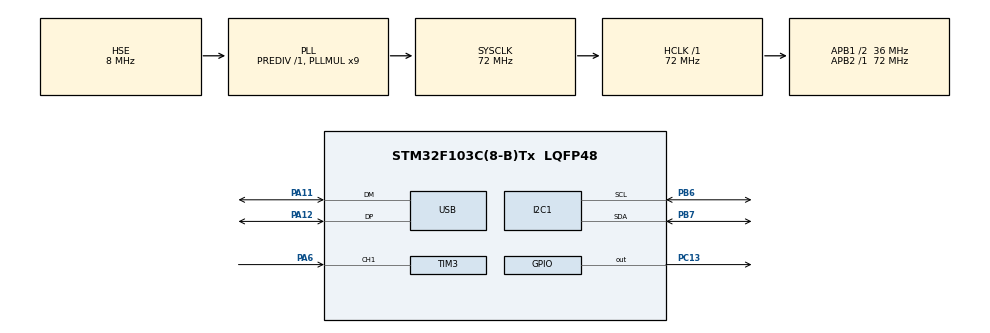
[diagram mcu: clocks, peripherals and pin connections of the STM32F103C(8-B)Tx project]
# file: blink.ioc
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Dma.I2C1_TX.0.Direction=DMA_MEMORY_TO_PERIPH
Dma.I2C1_TX.0.Instance=DMA1_Channel6
Dma.I2C1_TX.0.MemDataAlignment=DMA_MDATAALIGN_BYTE
Dma.I2C1_TX.0.MemInc=DMA_MINC_ENABLE
Dma.I2C1_TX.0.Mode=DMA_NORMAL
Dma.I2C1_TX.0.PeriphDataAlignment=DMA_PDATAALIGN_BYTE
Dma.I2C1_TX.0.PeriphInc=DMA_PINC_DISABLE
Dma.I2C1_TX.0.Priority=DMA_PRIORITY_LOW
Dma.Request0=I2C1_TX
FREERTOS.BinarySemaphores01=sendTelemetryToUsbSemaphore,Dynamic,NULL
FREERTOS.Tasks01=defaultTask,0,128,StartDefaultTask,Default,NULL
FREERTOS.configTOTAL_HEAP_SIZE=6144
FREERTOS.configUSE_COUNTING_SEMAPHORES=1
Mcu.Family=STM32F1
Mcu.Name=STM32F103C(8-B)Tx
Mcu.Package=LQFP48
NVIC.DMA1_Channel6_IRQn=true\:5\:0\:false\:false\:true\:true\:false
NVIC.I2C1_ER_IRQn=true\:5\:0\:false\:false\:true\:true\:true
NVIC.I2C1_EV_IRQn=true\:5\:0\:false\:false\:true\:true\:true
NVIC.PriorityGroup=NVIC_PRIORITYGROUP_4
NVIC.TIM3_IRQn=true\:5\:0\:false\:false\:true\:true\:true
NVIC.TIM4_IRQn=true\:0\:0\:false\:false\:true\:false\:false
NVIC.TimeBase=TIM4_IRQn
NVIC.TimeBaseIP=TIM4
NVIC.USB_LP_CAN1_RX0_IRQn=true\:5\:0\:false\:false\:true\:true\:false
PA11.Mode=Device
PA11.Signal=USB_DM
PA12.Mode=Device
PA12.Signal=USB_DP
PA13.Mode=Serial_Wire
PA13.Signal=SYS_JTMS-SWDIO
PA14.Mode=Serial_Wire
PA14.Signal=SYS_JTCK-SWCLK
PA6.Signal=S_TIM3_CH1
PB6.Mode=I2C
PB6.Signal=I2C1_SCL
PB7.Mode=I2C
PB7.Signal=I2C1_SDA
PC13-TAMPER-RTC.Signal=GPIO_Output
PD0-OSC_IN.Mode=HSE-External-Oscillator
PD0-OSC_IN.Signal=RCC_OSC_IN
PD1-OSC_OUT.Mode=HSE-External-Oscillator
PD1-OSC_OUT.Signal=RCC_OSC_OUT
ProjectManager.HeapSize=0x200
ProjectManager.StackSize=0x400
ProjectManager.TargetToolchain=SW4STM32
RCC.AHBFreq_Value=72000000
RCC.APB1CLKDivider=RCC_HCLK_DIV2
RCC.APB1Freq_Value=36000000
RCC.APB1TimFreq_Value=72000000
RCC.APB2Freq_Value=72000000
RCC.APB2TimFreq_Value=72000000
RCC.HCLKFreq_Value=72000000
RCC.PLLMUL=RCC_PLL_MUL9
RCC.PLLSourceVirtual=RCC_PLLSOURCE_HSE
RCC.SYSCLKFreq_VALUE=72000000
RCC.SYSCLKSource=RCC_SYSCLKSOURCE_PLLCLK
RCC.USBFreq_Value=48000000
RCC.USBPrescaler=RCC_USBCLKSOURCE_PLL_DIV1_5
SH.S_TIM3_CH1.0=TIM3_CH1,Input_Capture1_from_TI1
TIM3.Channel-Input_Capture1_from_TI1=TIM_CHANNEL_1
TIM3.ICPolarity_CH1=TIM_INPUTCHANNELPOLARITY_FALLING
TIM3.Period=65534
TIM3.Prescaler=71
USB_DEVICE.CLASS_NAME_FS=CDC
USB_DEVICE.VirtualMode=Cdc
USB_DEVICE.VirtualModeFS=Cdc_FS
VP_FREERTOS_VS_ENABLE.Mode=Enabled
VP_SYS_VS_tim4.Mode=TIM4
VP_USB_DEVICE_VS_USB_DEVICE_CDC_FS.Mode=CDC_FS
board=blink

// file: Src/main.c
/**
  ******************************************************************************
  * File Name          : main.c
  * Description        : Main program body
  ******************************************************************************
  * This notice applies to any and all portions of this file
  * that are not between comment pairs USER CODE BEGIN and
  * USER CODE END. Other portions of this file, whether
  * inserted by the user or by software development tools
  * are owned by their respective copyright owners.
  *
  * Copyright (c) 2018 STMicroelectronics International N.V.
  * All rights reserved.
  *
  * Redistribution and use in source and binary forms, with or without
  * modification, are permitted, provided that the following conditions are met:
  *
  * 1. Redistribution of source code must retain the above copyright notice,
  *    this list of conditions and the following disclaimer.
  * 2. Redistributions in binary form must reproduce the above copyright notice,
  *    this list of conditions and the following disclaimer in the documentation
  *    and/or other materials provided with the distribution.
  * 3. Neither the name of STMicroelectronics nor the names of other
  *    contributors to this software may be used to endorse or promote products
  *    derived from this software without specific written permission.
  * 4. This software, including modifications and/or derivative works of this
  *    software, must execute solely and exclusively on microcontroller or
  *    microprocessor devices manufactured by or for STMicroelectronics.
  * 5. Redistribution and use of this software other than as permitted under
  *    this license is void and will automatically terminate your rights under
  *    this license.
  *
  * THIS SOFTWARE IS PROVIDED BY STMICROELECTRONICS AND CONTRIBUTORS "AS IS"
  * AND ANY EXPRESS, IMPLIED OR STATUTORY WARRANTIES, INCLUDING, BUT NOT
  * LIMITED TO, THE IMPLIED WARRANTIES OF MERCHANTABILITY, FITNESS FOR A
  * PARTICULAR PURPOSE AND NON-INFRINGEMENT OF THIRD PARTY INTELLECTUAL PROPERTY
  * RIGHTS ARE DISCLAIMED TO THE FULLEST EXTENT PERMITTED BY LAW. IN NO EVENT
  * SHALL STMICROELECTRONICS OR CONTRIBUTORS BE LIABLE FOR ANY DIRECT, INDIRECT,
  * INCIDENTAL, SPECIAL, EXEMPLARY, OR CONSEQUENTIAL DAMAGES (INCLUDING, BUT NOT
  * LIMITED TO, PROCUREMENT OF SUBSTITUTE GOODS OR SERVICES; LOSS OF USE, DATA,
  * OR PROFITS; OR BUSINESS INTERRUPTION) HOWEVER CAUSED AND ON ANY THEORY OF
  * LIABILITY, WHETHER IN CONTRACT, STRICT LIABILITY, OR TORT (INCLUDING
  * NEGLIGENCE OR OTHERWISE) ARISING IN ANY WAY OUT OF THE USE OF THIS SOFTWARE,
  * EVEN IF ADVISED OF THE POSSIBILITY OF SUCH DAMAGE.
  *
  ******************************************************************************
  */

#include "main.h"
#include "stm32f1xx_hal.h"
#include "cmsis_os.h"
#include "usb_device.h"

/* USER CODE BEGIN Includes */
#include <lesson5.h>
/* USER CODE END Includes */

I2C_HandleTypeDef hi2c1;
DMA_HandleTypeDef hdma_i2c1_tx;

TIM_HandleTypeDef htim3;

//osThreadId defaultTaskHandle;
osSemaphoreId sendTelemetryToUsbSemaphoreHandle;

/* USER CODE BEGIN PV */
/* Private variables ---------------------------------------------------------*/
osThreadId displayOutputTask;
osThreadId tempratureTask;
osThreadId sendTelemetryToUsb;
/* USER CODE END PV */

void SystemClock_Config(void);
static void MX_GPIO_Init(void);
static void MX_DMA_Init(void);
static void MX_I2C1_Init(void);
static void MX_TIM3_Init(void);
//void StartDefaultTask(void const * argument);

/* USER CODE BEGIN PFP */

/* Private function prototypes -----------------------------------------------*/

/* USER CODE END PFP */

int main(void)
{

  /* MCU Configuration----------------------------------------------------------*/

  /* Reset of all peripherals, Initializes the Flash interface and the Systick. */
  HAL_Init();

  /* Configure the system clock */
  SystemClock_Config();

  /* Initialize all configured peripherals */
  MX_GPIO_Init();
  MX_DMA_Init();
  MX_I2C1_Init();
  MX_TIM3_Init();

  /* USER CODE BEGIN 2 */
  MX_USB_DEVICE_Init();
  /* USER CODE END 2 */

  /* Create the semaphores(s) */
  /* definition and creation of sendTelemetryToUsbSemaphore */
  osSemaphoreDef(sendTelemetryToUsbSemaphore);
  sendTelemetryToUsbSemaphoreHandle = osSemaphoreCreate(osSemaphore(sendTelemetryToUsbSemaphore), 1);

  /* Create the thread(s) */
  /* definition and creation of defaultTask */
//  osThreadDef(defaultTask, StartDefaultTask, osPriorityNormal, 0, 128);
//  defaultTaskHandle = osThreadCreate(osThread(defaultTask), NULL);

  /* USER CODE BEGIN RTOS_THREADS */
  osThreadDef(sendTelemetryToUsb, SendTelemetryToUsb, osPriorityRealtime, 1, 128);
  sendTelemetryToUsb = osThreadCreate(osThread(sendTelemetryToUsb), NULL);

  osThreadDef(tempratureTask, TemperatureTask, osPriorityAboveNormal, 1, 128);
  tempratureTask = osThreadCreate(osThread(tempratureTask), NULL);

  osThreadDef(displayOutputTask, DisplayOutputTask, osPriorityNormal, 1, 128);
  displayOutputTask = osThreadCreate(osThread(displayOutputTask), NULL);
  /* USER CODE END RTOS_THREADS */

  /* Start scheduler */
  osKernelStart();

  /* We should never get here as control is now taken by the scheduler */

  /* Infinite loop */
  while (1) {

  }

}

/** System Clock Configuration
*/
void SystemClock_Config(void)
{

  RCC_OscInitTypeDef RCC_OscInitStruct;
  RCC_ClkInitTypeDef RCC_ClkInitStruct;
  RCC_PeriphCLKInitTypeDef PeriphClkInit;

    /**Initializes the CPU, AHB and APB busses clocks
    */
  RCC_OscInitStruct.OscillatorType = RCC_OSCILLATORTYPE_HSE;
  RCC_OscInitStruct.HSEState = RCC_HSE_ON;
  RCC_OscInitStruct.HSEPredivValue = RCC_HSE_PREDIV_DIV1;
  RCC_OscInitStruct.HSIState = RCC_HSI_ON;
  RCC_OscInitStruct.PLL.PLLState = RCC_PLL_ON;
  RCC_OscInitStruct.PLL.PLLSource = RCC_PLLSOURCE_HSE;
  RCC_OscInitStruct.PLL.PLLMUL = RCC_PLL_MUL9;
  if (HAL_RCC_OscConfig(&RCC_OscInitStruct) != HAL_OK)
  {
    _Error_Handler(__FILE__, __LINE__);
  }

    /**Initializes the CPU, AHB and APB busses clocks
    */
  RCC_ClkInitStruct.ClockType = RCC_CLOCKTYPE_HCLK|RCC_CLOCKTYPE_SYSCLK
                              |RCC_CLOCKTYPE_PCLK1|RCC_CLOCKTYPE_PCLK2;
  RCC_ClkInitStruct.SYSCLKSource = RCC_SYSCLKSOURCE_PLLCLK;
  RCC_ClkInitStruct.AHBCLKDivider = RCC_SYSCLK_DIV1;
  RCC_ClkInitStruct.APB1CLKDivider = RCC_HCLK_DIV2;
  RCC_ClkInitStruct.APB2CLKDivider = RCC_HCLK_DIV1;

  if (HAL_RCC_ClockConfig(&RCC_ClkInitStruct, FLASH_LATENCY_2) != HAL_OK)
  {
    _Error_Handler(__FILE__, __LINE__);
  }

  PeriphClkInit.PeriphClockSelection = RCC_PERIPHCLK_USB;
  PeriphClkInit.UsbClockSelection = RCC_USBCLKSOURCE_PLL_DIV1_5;
  if (HAL_RCCEx_PeriphCLKConfig(&PeriphClkInit) != HAL_OK)
  {
    _Error_Handler(__FILE__, __LINE__);
  }

    /**Configure the Systick interrupt time
    */
  HAL_SYSTICK_Config(HAL_RCC_GetHCLKFreq()/1000);

    /**Configure the Systick
    */
  HAL_SYSTICK_CLKSourceConfig(SYSTICK_CLKSOURCE_HCLK);

  /* SysTick_IRQn interrupt configuration */
  HAL_NVIC_SetPriority(SysTick_IRQn, 15, 0);
}

/* I2C1 init function */
static void MX_I2C1_Init(void)
{

  hi2c1.Instance = I2C1;
  hi2c1.Init.ClockSpeed = 100000;
  hi2c1.Init.DutyCycle = I2C_DUTYCYCLE_2;
  hi2c1.Init.OwnAddress1 = 0;
  hi2c1.Init.AddressingMode = I2C_ADDRESSINGMODE_7BIT;
  hi2c1.Init.DualAddressMode = I2C_DUALADDRESS_DISABLE;
  hi2c1.Init.OwnAddress2 = 0;
  hi2c1.Init.GeneralCallMode = I2C_GENERALCALL_DISABLE;
  hi2c1.Init.NoStretchMode = I2C_NOSTRETCH_DISABLE;
  if (HAL_I2C_Init(&hi2c1) != HAL_OK)
  {
    _Error_Handler(__FILE__, __LINE__);
  }

}

/* TIM3 init function */
static void MX_TIM3_Init(void)
{

  TIM_MasterConfigTypeDef sMasterConfig;
  TIM_IC_InitTypeDef sConfigIC;

  htim3.Instance = TIM3;
  htim3.Init.Prescaler = 71;
  htim3.Init.CounterMode = TIM_COUNTERMODE_UP;
  htim3.Init.Period = 65534;
  htim3.Init.ClockDivision = TIM_CLOCKDIVISION_DIV1;
  htim3.Init.AutoReloadPreload = TIM_AUTORELOAD_PRELOAD_DISABLE;
  if (HAL_TIM_IC_Init(&htim3) != HAL_OK)
  {
    _Error_Handler(__FILE__, __LINE__);
  }

  sMasterConfig.MasterOutputTrigger = TIM_TRGO_RESET;
  sMasterConfig.MasterSlaveMode = TIM_MASTERSLAVEMODE_DISABLE;
  if (HAL_TIMEx_MasterConfigSynchronization(&htim3, &sMasterConfig) != HAL_OK)
  {
    _Error_Handler(__FILE__, __LINE__);
  }

  sConfigIC.ICPolarity = TIM_INPUTCHANNELPOLARITY_FALLING;
  sConfigIC.ICSelection = TIM_ICSELECTION_DIRECTTI;
  sConfigIC.ICPrescaler = TIM_ICPSC_DIV1;
  sConfigIC.ICFilter = 0;
  if (HAL_TIM_IC_ConfigChannel(&htim3, &sConfigIC, TIM_CHANNEL_1) != HAL_OK)
  {
    _Error_Handler(__FILE__, __LINE__);
  }

}

static void MX_DMA_Init(void)
{
  /* DMA controller clock enable */
  __HAL_RCC_DMA1_CLK_ENABLE();

  /* DMA interrupt init */
  /* DMA1_Channel6_IRQn interrupt configuration */
  HAL_NVIC_SetPriority(DMA1_Channel6_IRQn, 5, 0);
  HAL_NVIC_EnableIRQ(DMA1_Channel6_IRQn);

}

/** Configure pins as
        * Analog
        * Input
        * Output
        * EVENT_OUT
        * EXTI
*/
static void MX_GPIO_Init(void)
{

  GPIO_InitTypeDef GPIO_InitStruct;

  /* GPIO Ports Clock Enable */
  __HAL_RCC_GPIOC_CLK_ENABLE();
  __HAL_RCC_GPIOD_CLK_ENABLE();
  __HAL_RCC_GPIOA_CLK_ENABLE();
  __HAL_RCC_GPIOB_CLK_ENABLE();

  /*Configure GPIO pin Output Level */
  HAL_GPIO_WritePin(GPIOC, GPIO_PIN_13, GPIO_PIN_RESET);

  /*Configure GPIO pin : PC13 */
  GPIO_InitStruct.Pin = GPIO_PIN_13;
  GPIO_InitStruct.Mode = GPIO_MODE_OUTPUT_PP;
  GPIO_InitStruct.Speed = GPIO_SPEED_FREQ_LOW;
  HAL_GPIO_Init(GPIOC, &GPIO_InitStruct);

}

/* StartDefaultTask function */
void StartDefaultTask(void const * argument)
{
  /* init code for USB_DEVICE */
  MX_USB_DEVICE_Init();

  for(;;)
  {
    osDelay(1);
  }
}

void HAL_TIM_PeriodElapsedCallback(TIM_HandleTypeDef *htim)
{
  if (htim->Instance == TIM4) {
    HAL_IncTick();
  }
}

void _Error_Handler(char * file, int line)
{
    while (1) {
    }
}

/************************ (C) COPYRIGHT STMicroelectronics *****END OF FILE****/
